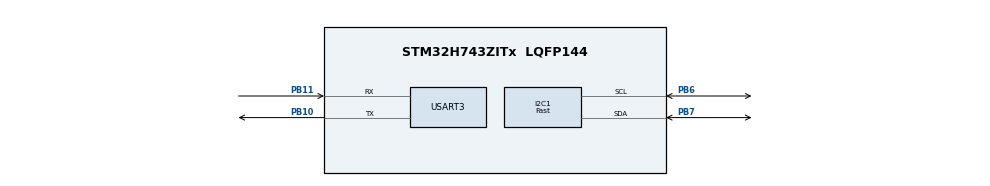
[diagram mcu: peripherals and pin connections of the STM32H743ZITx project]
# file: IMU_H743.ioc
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FREERTOS.Tasks01=IMUTask,0,128,StartDefaultTask,Default,NULL,Dynamic,NULL,NULL
I2C1.I2C_Speed_Mode=I2C_Fast
I2C1.Speed=296
I2C1.Timing=0x006021AB
Mcu.Family=STM32H7
Mcu.Name=STM32H743ZITx
Mcu.Package=LQFP144
NVIC.PriorityGroup=NVIC_PRIORITYGROUP_4
NVIC.TIM1_UP_IRQn=true\:0\:0\:false\:false\:true\:false\:false
NVIC.TimeBase=TIM1_UP_IRQn
NVIC.TimeBaseIP=TIM1
NVIC.USART3_IRQn=true\:5\:0\:false\:false\:true\:true\:true
PB10.Mode=Asynchronous
PB10.Signal=USART3_TX
PB11.Mode=Asynchronous
PB11.Signal=USART3_RX
PB6.Mode=I2C
PB6.Signal=I2C1_SCL
PB7.Mode=I2C
PB7.Signal=I2C1_SDA
ProjectManager.HeapSize=0x200
ProjectManager.StackSize=0x400
ProjectManager.TargetToolchain=SW4STM32
RCC.ADCFreq_Value=129000000
RCC.APB1Freq_Value=64000000
RCC.APB2Freq_Value=64000000
RCC.APB3Freq_Value=64000000
RCC.APB4Freq_Value=64000000
RCC.CortexFreq_Value=64000000
RCC.HCLKFreq_Value=64000000
RCC.SYSCLKFreq_VALUE=64000000
RCC.USBFreq_Value=129000000
USART3.VirtualMode-Asynchronous=VM_ASYNC
USART3.WordLength=WORDLENGTH_8B
VP_FREERTOS_VS_ENABLE.Mode=Enabled
VP_SYS_VS_tim1.Mode=TIM1
board=IMU_H743

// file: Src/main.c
/**
  ******************************************************************************
  * File Name          : main.c
  * Description        : Main program body
  ******************************************************************************
  * This notice applies to any and all portions of this file
  * that are not between comment pairs USER CODE BEGIN and
  * USER CODE END. Other portions of this file, whether
  * inserted by the user or by software development tools
  * are owned by their respective copyright owners.
  *
  * Copyright (c) 2018 STMicroelectronics International N.V.
  * All rights reserved.
  *
  * Redistribution and use in source and binary forms, with or without
  * modification, are permitted, provided that the following conditions are met:
  *
  * 1. Redistribution of source code must retain the above copyright notice,
  *    this list of conditions and the following disclaimer.
  * 2. Redistributions in binary form must reproduce the above copyright notice,
  *    this list of conditions and the following disclaimer in the documentation
  *    and/or other materials provided with the distribution.
  * 3. Neither the name of STMicroelectronics nor the names of other
  *    contributors to this software may be used to endorse or promote products
  *    derived from this software without specific written permission.
  * 4. This software, including modifications and/or derivative works of this
  *    software, must execute solely and exclusively on microcontroller or
  *    microprocessor devices manufactured by or for STMicroelectronics.
  * 5. Redistribution and use of this software other than as permitted under
  *    this license is void and will automatically terminate your rights under
  *    this license.
  *
  * THIS SOFTWARE IS PROVIDED BY STMICROELECTRONICS AND CONTRIBUTORS "AS IS"
  * AND ANY EXPRESS, IMPLIED OR STATUTORY WARRANTIES, INCLUDING, BUT NOT
  * LIMITED TO, THE IMPLIED WARRANTIES OF MERCHANTABILITY, FITNESS FOR A
  * PARTICULAR PURPOSE AND NON-INFRINGEMENT OF THIRD PARTY INTELLECTUAL PROPERTY
  * RIGHTS ARE DISCLAIMED TO THE FULLEST EXTENT PERMITTED BY LAW. IN NO EVENT
  * SHALL STMICROELECTRONICS OR CONTRIBUTORS BE LIABLE FOR ANY DIRECT, INDIRECT,
  * INCIDENTAL, SPECIAL, EXEMPLARY, OR CONSEQUENTIAL DAMAGES (INCLUDING, BUT NOT
  * LIMITED TO, PROCUREMENT OF SUBSTITUTE GOODS OR SERVICES; LOSS OF USE, DATA,
  * OR PROFITS; OR BUSINESS INTERRUPTION) HOWEVER CAUSED AND ON ANY THEORY OF
  * LIABILITY, WHETHER IN CONTRACT, STRICT LIABILITY, OR TORT (INCLUDING
  * NEGLIGENCE OR OTHERWISE) ARISING IN ANY WAY OUT OF THE USE OF THIS SOFTWARE,
  * EVEN IF ADVISED OF THE POSSIBILITY OF SUCH DAMAGE.
  *
  ******************************************************************************
  */

#include "main.h"
#include "stm32h7xx_hal.h"
#include "cmsis_os.h"
#include "i2c.h"
#include "usart.h"
#include "gpio.h"

/* USER CODE BEGIN PV */
/* Private variables ---------------------------------------------------------*/

/* USER CODE END PV */

void SystemClock_Config(void);
void MX_FREERTOS_Init(void);

/* USER CODE BEGIN PFP */
/* Private function prototypes -----------------------------------------------*/

/* USER CODE END PFP */

int main(void)
{

  /* MCU Configuration----------------------------------------------------------*/

  /* Reset of all peripherals, Initializes the Flash interface and the Systick. */
  HAL_Init();

  /* Configure the system clock */
  SystemClock_Config();

  /* Initialize all configured peripherals */
  MX_GPIO_Init();
  MX_USART3_UART_Init();
  MX_I2C1_Init();

  /* Call init function for freertos objects (in freertos.c) */
  MX_FREERTOS_Init();

  /* Start scheduler */
  osKernelStart();

  /* We should never get here as control is now taken by the scheduler */

  /* Infinite loop */
  while (1)
  {

  }

}

/** System Clock Configuration
*/
void SystemClock_Config(void)
{

  RCC_OscInitTypeDef RCC_OscInitStruct;
  RCC_ClkInitTypeDef RCC_ClkInitStruct;
  RCC_PeriphCLKInitTypeDef PeriphClkInitStruct;

    /**Supply configuration update enable
    */
  MODIFY_REG(PWR->CR3, PWR_CR3_SCUEN, 0);

    /**Configure the main internal regulator output voltage
    */
  __HAL_PWR_VOLTAGESCALING_CONFIG(PWR_REGULATOR_VOLTAGE_SCALE1);

  while ((PWR->D3CR & (PWR_D3CR_VOSRDY)) != PWR_D3CR_VOSRDY)
  {

  }
    /**Initializes the CPU, AHB and APB busses clocks
    */
  RCC_OscInitStruct.OscillatorType = RCC_OSCILLATORTYPE_HSI;
  RCC_OscInitStruct.HSIState = RCC_HSI_DIV1;
  RCC_OscInitStruct.HSICalibrationValue = 16;
  RCC_OscInitStruct.PLL.PLLState = RCC_PLL_NONE;
  if (HAL_RCC_OscConfig(&RCC_OscInitStruct) != HAL_OK)
  {
    _Error_Handler(__FILE__, __LINE__);
  }

    /**Initializes the CPU, AHB and APB busses clocks
    */
  RCC_ClkInitStruct.ClockType = RCC_CLOCKTYPE_HCLK|RCC_CLOCKTYPE_SYSCLK
                              |RCC_CLOCKTYPE_PCLK1|RCC_CLOCKTYPE_PCLK2
                              |RCC_CLOCKTYPE_D3PCLK1|RCC_CLOCKTYPE_D1PCLK1;
  RCC_ClkInitStruct.SYSCLKSource = RCC_SYSCLKSOURCE_HSI;
  RCC_ClkInitStruct.SYSCLKDivider = RCC_SYSCLK_DIV1;
  RCC_ClkInitStruct.AHBCLKDivider = RCC_HCLK_DIV1;
  RCC_ClkInitStruct.APB3CLKDivider = RCC_APB3_DIV1;
  RCC_ClkInitStruct.APB1CLKDivider = RCC_APB1_DIV1;
  RCC_ClkInitStruct.APB2CLKDivider = RCC_APB2_DIV1;
  RCC_ClkInitStruct.APB4CLKDivider = RCC_APB4_DIV1;

  if (HAL_RCC_ClockConfig(&RCC_ClkInitStruct, FLASH_LATENCY_0) != HAL_OK)
  {
    _Error_Handler(__FILE__, __LINE__);
  }

  PeriphClkInitStruct.PeriphClockSelection = RCC_PERIPHCLK_USART3|RCC_PERIPHCLK_I2C1;
  PeriphClkInitStruct.Usart234578ClockSelection = RCC_USART234578CLKSOURCE_D2PCLK1;
  PeriphClkInitStruct.I2c123ClockSelection = RCC_I2C123CLKSOURCE_D2PCLK1;
  if (HAL_RCCEx_PeriphCLKConfig(&PeriphClkInitStruct) != HAL_OK)
  {
    _Error_Handler(__FILE__, __LINE__);
  }

    /**Configure the Systick interrupt time
    */
  HAL_SYSTICK_Config(SystemCoreClock/1000);

    /**Configure the Systick
    */
  HAL_SYSTICK_CLKSourceConfig(SYSTICK_CLKSOURCE_HCLK);

  /* SysTick_IRQn interrupt configuration */
  HAL_NVIC_SetPriority(SysTick_IRQn, 15, 0);
}

void HAL_TIM_PeriodElapsedCallback(TIM_HandleTypeDef *htim)
{
  if (htim->Instance == TIM1) {
    HAL_IncTick();
  }
}

void _Error_Handler(char * file, int line)
{
  while(1)
  {
  }
}

/************************ (C) COPYRIGHT STMicroelectronics *****END OF FILE****/

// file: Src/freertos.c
/**
  ******************************************************************************
  * File Name          : freertos.c
  * Description        : Code for freertos applications
  ******************************************************************************
  * This notice applies to any and all portions of this file
  * that are not between comment pairs USER CODE BEGIN and
  * USER CODE END. Other portions of this file, whether
  * inserted by the user or by software development tools
  * are owned by their respective copyright owners.
  *
  * Copyright (c) 2018 STMicroelectronics International N.V.
  * All rights reserved.
  *
  * Redistribution and use in source and binary forms, with or without
  * modification, are permitted, provided that the following conditions are met:
  *
  * 1. Redistribution of source code must retain the above copyright notice,
  *    this list of conditions and the following disclaimer.
  * 2. Redistributions in binary form must reproduce the above copyright notice,
  *    this list of conditions and the following disclaimer in the documentation
  *    and/or other materials provided with the distribution.
  * 3. Neither the name of STMicroelectronics nor the names of other
  *    contributors to this software may be used to endorse or promote products
  *    derived from this software without specific written permission.
  * 4. This software, including modifications and/or derivative works of this
  *    software, must execute solely and exclusively on microcontroller or
  *    microprocessor devices manufactured by or for STMicroelectronics.
  * 5. Redistribution and use of this software other than as permitted under
  *    this license is void and will automatically terminate your rights under
  *    this license.
  *
  * THIS SOFTWARE IS PROVIDED BY STMICROELECTRONICS AND CONTRIBUTORS "AS IS"
  * AND ANY EXPRESS, IMPLIED OR STATUTORY WARRANTIES, INCLUDING, BUT NOT
  * LIMITED TO, THE IMPLIED WARRANTIES OF MERCHANTABILITY, FITNESS FOR A
  * PARTICULAR PURPOSE AND NON-INFRINGEMENT OF THIRD PARTY INTELLECTUAL PROPERTY
  * RIGHTS ARE DISCLAIMED TO THE FULLEST EXTENT PERMITTED BY LAW. IN NO EVENT
  * SHALL STMICROELECTRONICS OR CONTRIBUTORS BE LIABLE FOR ANY DIRECT, INDIRECT,
  * INCIDENTAL, SPECIAL, EXEMPLARY, OR CONSEQUENTIAL DAMAGES (INCLUDING, BUT NOT
  * LIMITED TO, PROCUREMENT OF SUBSTITUTE GOODS OR SERVICES; LOSS OF USE, DATA,
  * OR PROFITS; OR BUSINESS INTERRUPTION) HOWEVER CAUSED AND ON ANY THEORY OF
  * LIABILITY, WHETHER IN CONTRACT, STRICT LIABILITY, OR TORT (INCLUDING
  * NEGLIGENCE OR OTHERWISE) ARISING IN ANY WAY OUT OF THE USE OF THIS SOFTWARE,
  * EVEN IF ADVISED OF THE POSSIBILITY OF SUCH DAMAGE.
  *
  ******************************************************************************
  */

#include "FreeRTOS.h"
#include "task.h"
#include "cmsis_os.h"

/* USER CODE BEGIN Includes */
//#include "MPU6050.h"
#include "usart.h"
#include <stdio.h>
#include <stdlib.h>
#include "stm32h7xx_hal.h"
#include "i2c.h"
#include "usart.h"
#include "gpio.h"
/* USER CODE END Includes */

osThreadId IMUTaskHandle;

void StartDefaultTask(void const * argument);

void MX_FREERTOS_Init(void); /* (MISRA C 2004 rule 8.1) */

/* Hook prototypes */

/* Init FreeRTOS */

void MX_FREERTOS_Init(void) {

  /* Create the thread(s) */
  /* definition and creation of IMUTask */
  osThreadDef(IMUTask, StartDefaultTask, osPriorityNormal, 0, 128);
  IMUTaskHandle = osThreadCreate(osThread(IMUTask), NULL);

}

/* StartDefaultTask function */
void StartDefaultTask(void const * argument)
{

  /* USER CODE BEGIN StartDefaultTask */
  /* Infinite loop */
	uint16_t Xg=5;
  for(;;)
  {
	//	HAL_UART_Transmit(&huart3, &Xg, 2, 10);
    osDelay(1);
  }
  /* USER CODE END StartDefaultTask */
}

/************************ (C) COPYRIGHT STMicroelectronics *****END OF FILE****/
